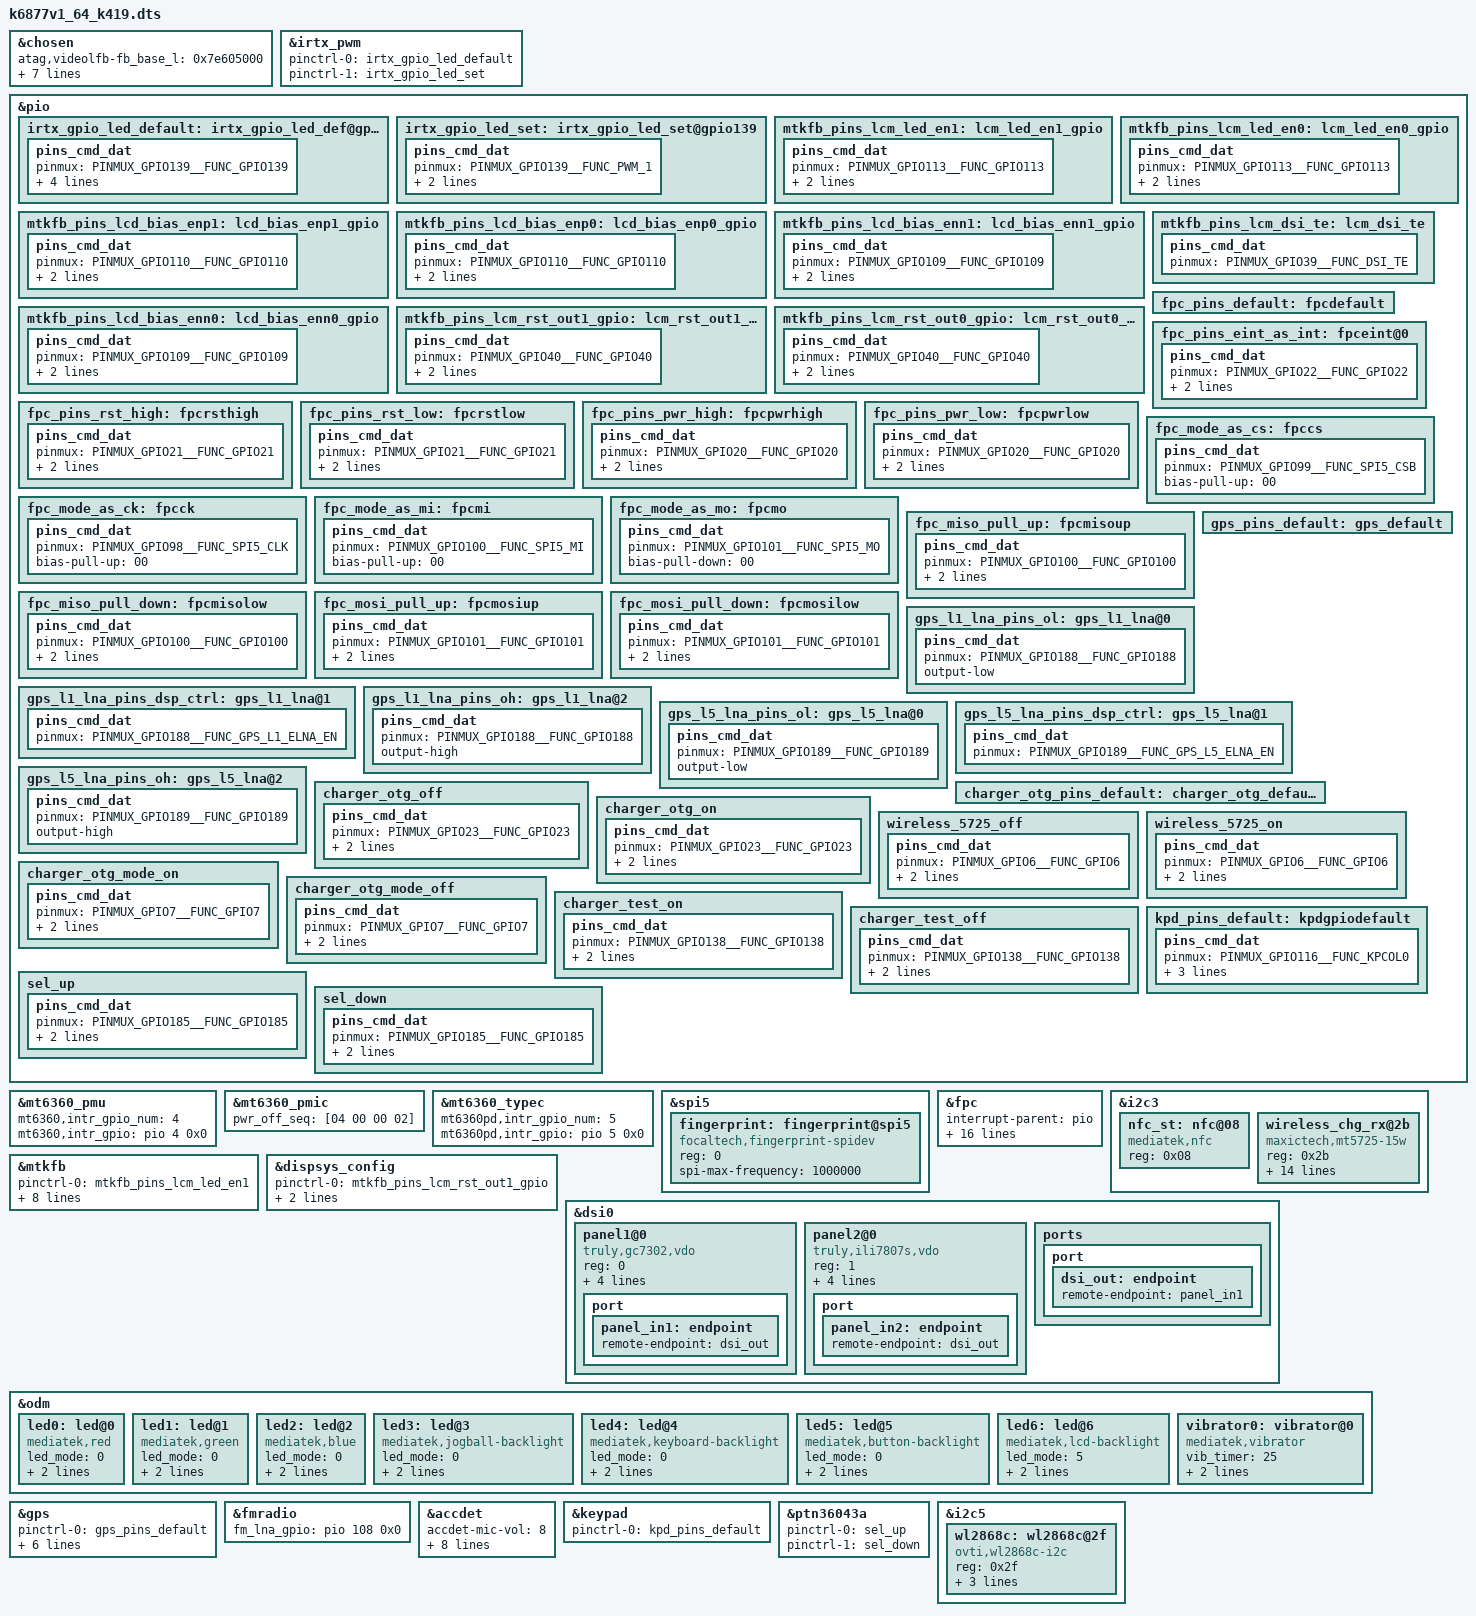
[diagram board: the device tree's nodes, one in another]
// SPDX-License-Identifier: GPL-2.0
/*
 * Copyright (c) 2021 MediaTek Inc.
 */

/dts-v1/;
/plugin/;
#include <dt-bindings/interrupt-controller/irq.h>
#include <dt-bindings/interrupt-controller/arm-gic.h>
#include <dt-bindings/pinctrl/mt6877-pinfunc.h>

/* chosen */
&chosen {
	atag,videolfb-fb_base_l = <0x7e605000>;
	atag,videolfb-fb_base_h = <0x0>;
	atag,videolfb-islcmfound = <1>;
	atag,videolfb-islcm_inited = <0>;
	atag,videolfb-fps= <6000>;
	atag,videolfb-vramSize= <0x1be0000>;
	atag,videolfb-lcmname=
		"gc7302_fhdp_dsi_vdo_auo_120hz_lcm_drv";
};

/* IRTX GPIO Start */
&irtx_pwm {
	pinctrl-names = "irtx_gpio_led_default", "irtx_gpio_led_set";
	pinctrl-0 = <&irtx_gpio_led_default>;
	pinctrl-1 = <&irtx_gpio_led_set>;
	status = "okay";
};
&pio {
	/* IRTX GPIO Settings -Start */
	/* default: GPIO0, output, high */
	irtx_gpio_led_default:irtx_gpio_led_def@gpio139 {
		pins_cmd_dat {
			pinmux = <PINMUX_GPIO139__FUNC_GPIO139>;
			slew-rate = <1>;
			bias-disable;
			output-low;
			input-schmitt-enable = <0>;
		};
	};

	irtx_gpio_led_set:irtx_gpio_led_set@gpio139 {
		pins_cmd_dat {
			pinmux = <PINMUX_GPIO139__FUNC_PWM_1>;
			slew-rate = <1>;
			output-high;
		};
	};
}; /* IRTX GPIO Settings -End */

&mt6360_pmu {
	mt6360,intr_gpio_num = <4>; /* direct defined GPIO num */
	mt6360,intr_gpio = <&pio 4 0x0>;
};

&mt6360_pmic {
	pwr_off_seq = [04 00 00 02];
};

&mt6360_typec {
	mt6360pd,intr_gpio_num = <5>; /* direct defined GPIO num */
	mt6360pd,intr_gpio = <&pio 5 0x0>;
};

&pio {
	mtkfb_pins_lcm_led_en1: lcm_led_en1_gpio {
		pins_cmd_dat {
			pinmux = <PINMUX_GPIO113__FUNC_GPIO113>;
			slew-rate = <1>;
			output-high;
		};
	};

	mtkfb_pins_lcm_led_en0: lcm_led_en0_gpio {
		pins_cmd_dat {
			pinmux = <PINMUX_GPIO113__FUNC_GPIO113>;
			slew-rate = <1>;
			output-low;
		};
	};

	mtkfb_pins_lcd_bias_enp1: lcd_bias_enp1_gpio {
		pins_cmd_dat {
			pinmux = <PINMUX_GPIO110__FUNC_GPIO110>;
			slew-rate = <1>;
			output-high;
		};
	};

	mtkfb_pins_lcd_bias_enp0: lcd_bias_enp0_gpio {
		pins_cmd_dat {
			pinmux = <PINMUX_GPIO110__FUNC_GPIO110>;
			slew-rate = <1>;
			output-low;
		};
	};

	mtkfb_pins_lcd_bias_enn1: lcd_bias_enn1_gpio {
		pins_cmd_dat {
			pinmux = <PINMUX_GPIO109__FUNC_GPIO109>;
			slew-rate = <1>;
			output-high;
		};
	};

	mtkfb_pins_lcd_bias_enn0: lcd_bias_enn0_gpio {
		pins_cmd_dat {
			pinmux = <PINMUX_GPIO109__FUNC_GPIO109>;
			slew-rate = <1>;
			output-low;
		};
	};

	mtkfb_pins_lcm_rst_out1_gpio: lcm_rst_out1_gpio {
		pins_cmd_dat {
			pinmux = <PINMUX_GPIO40__FUNC_GPIO40>;
			slew-rate = <1>;
			output-high;
		};
	};

	mtkfb_pins_lcm_rst_out0_gpio: lcm_rst_out0_gpio {
		pins_cmd_dat {
			pinmux = <PINMUX_GPIO40__FUNC_GPIO40>;
			slew-rate = <1>;
			output-low;
		};
	};
	mtkfb_pins_lcm_dsi_te: lcm_dsi_te {
		pins_cmd_dat {
			pinmux = <PINMUX_GPIO39__FUNC_DSI_TE>;
		};
	};
};

/* prize-add-pengzhipeng-20191011-start */
&spi5{
	#address-cells = <1>;
	#size-cells = <0>;
	fingerprint: fingerprint@spi5{
		compatible = "focaltech,fingerprint-spidev";
		reg = <0>;
		spi-max-frequency = <1000000>;
		status = "okay";
	};
};

&fpc {
	interrupt-parent = <&pio>;
	interrupts = <22 IRQ_TYPE_EDGE_RISING 22 0>;
	VFP-supply = <&mt_pmic_vfp_ldo_reg>;
	pinctrl-names = "default",
		"fpc_eint_as_int",
		"fpc_pins_rst_high", "fpc_pins_rst_low",
		"fpc_pins_pwr_high", "fpc_pins_pwr_low",
		"fpc_mode_as_cs", "fpc_mode_as_ck",
		"fpc_mode_as_mi", "fpc_mode_as_mo",
		"fpc_miso_pull_up", "fpc_miso_pull_down",
		"fpc_mosi_pull_up", "fpc_mosi_pull_down";
	pinctrl-0 = <&fpc_pins_default>;
	pinctrl-1 = <&fpc_pins_eint_as_int>;
	pinctrl-2 = <&fpc_pins_rst_high>;
	pinctrl-3 = <&fpc_pins_rst_low>;
	pinctrl-4 = <&fpc_pins_pwr_high>;
	pinctrl-5 = <&fpc_pins_pwr_low>;
	pinctrl-6 = <&fpc_mode_as_cs>;
	pinctrl-7 = <&fpc_mode_as_ck>;
	pinctrl-8= <&fpc_mode_as_mi>;
	pinctrl-9 = <&fpc_mode_as_mo>;
	pinctrl-10 = <&fpc_miso_pull_up>;
	pinctrl-11 = <&fpc_miso_pull_down>;
	pinctrl-12 = <&fpc_mosi_pull_up>;
	pinctrl-13 = <&fpc_mosi_pull_down>;
	status = "okay";
};
&pio {
	fpc_pins_default: fpcdefault {
	};

	fpc_pins_eint_as_int: fpceint@0 {
		pins_cmd_dat {
			pinmux = <PINMUX_GPIO22__FUNC_GPIO22>;
			slew-rate = <0>;
			bias-disable;
		};
	};
	fpc_pins_rst_high: fpcrsthigh {
		pins_cmd_dat {
			pinmux = <PINMUX_GPIO21__FUNC_GPIO21>;
			slew-rate = <1>;
			output-high;
		};
	};
	fpc_pins_rst_low: fpcrstlow {
		pins_cmd_dat {
			pinmux = <PINMUX_GPIO21__FUNC_GPIO21>;
			slew-rate = <1>;
			output-low;
		};
	};
	fpc_pins_pwr_high: fpcpwrhigh {
		pins_cmd_dat {
			pinmux = <PINMUX_GPIO20__FUNC_GPIO20>;
			slew-rate = <1>;
			output-high;
		};
	};
	fpc_pins_pwr_low: fpcpwrlow {
		pins_cmd_dat {
			pinmux = <PINMUX_GPIO20__FUNC_GPIO20>;
			slew-rate = <1>;
			output-low;
		};
	};	
	fpc_mode_as_cs: fpccs {
		pins_cmd_dat {
			pinmux = <PINMUX_GPIO99__FUNC_SPI5_CSB>;
			bias-pull-up = <00>;
		};
	};
	fpc_mode_as_ck: fpcck {
		pins_cmd_dat {
			pinmux = <PINMUX_GPIO98__FUNC_SPI5_CLK>;
			bias-pull-up = <00>;
		};
	};
	fpc_mode_as_mi: fpcmi {
		pins_cmd_dat {
			pinmux = <PINMUX_GPIO100__FUNC_SPI5_MI>;
			bias-pull-up = <00>;
		};
	};
	fpc_mode_as_mo: fpcmo {
		pins_cmd_dat {
			pinmux = <PINMUX_GPIO101__FUNC_SPI5_MO>;
			bias-pull-down = <00>;
		};
	};
	fpc_miso_pull_up: fpcmisoup {
		pins_cmd_dat {
			pinmux = <PINMUX_GPIO100__FUNC_GPIO100>;
			slew-rate = <1>;
			output-high;
		};
	};
	fpc_miso_pull_down: fpcmisolow {
		pins_cmd_dat {
			pinmux = <PINMUX_GPIO100__FUNC_GPIO100>;
			slew-rate = <1>;
			output-low;
		};
	};
	fpc_mosi_pull_up: fpcmosiup {
		pins_cmd_dat {
			pinmux = <PINMUX_GPIO101__FUNC_GPIO101>;
			slew-rate = <1>;
			output-high;
		};
	};
	fpc_mosi_pull_down: fpcmosilow {
		pins_cmd_dat {
			pinmux = <PINMUX_GPIO101__FUNC_GPIO101>;
			slew-rate = <1>;
			output-low;
		};
	};
};
/* prize-add-pengzhipeng-20191011-end */
/* prize-add nfc-pengzhipeng-20220316-start */
/*******************************************
* nfc st21
*******************************************/
&i2c3 {
	nfc_st:nfc@08 {
		compatible = "mediatek,nfc";
		reg = <0x08>;
		status = "okay";
	};
};
/* prize-add nfc-pengzhipeng-20220316-end */
&mtkfb {
	pinctrl-names = "lcm_led_en1_gpio", "lcm_led_en0_gpio",
		"lcd_bias_enp1_gpio", "lcd_bias_enp0_gpio",
		"lcd_bias_enn1_gpio", "lcd_bias_enn0_gpio",
		"lcm_rst_out1_gpio", "lcm_rst_out0_gpio",
		"mode_te_te";
	pinctrl-0 = <&mtkfb_pins_lcm_led_en1>;
	pinctrl-1 = <&mtkfb_pins_lcm_led_en0>;
	pinctrl-2 = <&mtkfb_pins_lcd_bias_enp1>;
	pinctrl-3 = <&mtkfb_pins_lcd_bias_enp0>;
	pinctrl-4 = <&mtkfb_pins_lcd_bias_enn1>;
	pinctrl-5 = <&mtkfb_pins_lcd_bias_enn0>;
	pinctrl-6 = <&mtkfb_pins_lcm_rst_out1_gpio>;
	pinctrl-7 = <&mtkfb_pins_lcm_rst_out0_gpio>;
	pinctrl-8 = <&mtkfb_pins_lcm_dsi_te>;
	status = "okay";
};
&dispsys_config {
	pinctrl-names =
		"lcm_rst_out1_gpio", "lcm_rst_out0_gpio",
		"mode_te_te";
	pinctrl-0 = <&mtkfb_pins_lcm_rst_out1_gpio>;
	pinctrl-1 = <&mtkfb_pins_lcm_rst_out0_gpio>;
	pinctrl-2 = <&mtkfb_pins_lcm_dsi_te>;
	status = "okay";
};

&dsi0 {
	status = "okay";
	#address-cells = <1>;
	#size-cells = <0>;
	panel1@0 {
		compatible = "truly,gc7302,vdo";
		reg = <0>;
		pm-enable-gpios = <&pio 107 0>;
		reset-gpios = <&pio 40 0>;
		ldo18-gpios = <&pio 184 0>;
		bias-gpios = <&pio 110 0>,
			<&pio 109 0>;
		pinctrl-names = "default";
		port {
			panel_in1: endpoint {
				remote-endpoint = <&dsi_out>;
			};
		};
	};
	panel2@0 {
		compatible = "truly,ili7807s,vdo";
		reg = <1>;
		pm-enable-gpios = <&pio 107 0>;
		reset-gpios = <&pio 40 0>;
		ldo18-gpios = <&pio 184 0>;
		bias-gpios = <&pio 110 0>,
			<&pio 109 0>;
		pinctrl-names = "default";
		port {
			panel_in2: endpoint {
				remote-endpoint = <&dsi_out>;
			};
		};
	};
	ports {
		port {
			dsi_out: endpoint {
				remote-endpoint = <&panel_in1>;
			};
		};
	};
};

&odm {
	led0:led@0 {
		compatible = "mediatek,red";
		led_mode = <0>;
		data = <1>;
		pwm_config = <0 0 0 0 0>;
	};
	led1:led@1 {
		compatible = "mediatek,green";
		led_mode = <0>;
		data = <1>;
		pwm_config = <0 0 0 0 0>;
	};
	led2:led@2 {
		compatible = "mediatek,blue";
		led_mode = <0>;
		data = <1>;
		pwm_config = <0 0 0 0 0>;
	};
	led3:led@3 {
		compatible = "mediatek,jogball-backlight";
		led_mode = <0>;
		data = <1>;
		pwm_config = <0 0 0 0 0>;
	};
	led4:led@4 {
		compatible = "mediatek,keyboard-backlight";
		led_mode = <0>;
		data = <1>;
		pwm_config = <0 0 0 0 0>;
	};
	led5:led@5 {
		compatible = "mediatek,button-backlight";
		led_mode = <0>;
		data = <1>;
		pwm_config = <0 0 0 0 0>;
	};
	led6:led@6 {
		compatible = "mediatek,lcd-backlight";
		led_mode = <5>;
		data = <1>;
		led_config = <8 11>;
	};
	vibrator0:vibrator@0 {
		compatible = "mediatek,vibrator";
		vib_timer = <25>;
		vib_limit = <11>;
		vib_vol= <11>;
	};
};

/* GPS GPIO standardization start */
&pio {
	gps_pins_default: gps_default {
	};
	gps_l1_lna_pins_ol: gps_l1_lna@0 {
		pins_cmd_dat {
			pinmux = <PINMUX_GPIO188__FUNC_GPIO188>;
			output-low;
		};
	};
	gps_l1_lna_pins_dsp_ctrl: gps_l1_lna@1 {
		pins_cmd_dat {
			pinmux = <PINMUX_GPIO188__FUNC_GPS_L1_ELNA_EN>;
		};
	};
	gps_l1_lna_pins_oh: gps_l1_lna@2 {
		pins_cmd_dat {
			pinmux = <PINMUX_GPIO188__FUNC_GPIO188>;
			output-high;
		};
	};
	gps_l5_lna_pins_ol: gps_l5_lna@0 {
		pins_cmd_dat {
			pinmux = <PINMUX_GPIO189__FUNC_GPIO189>;
			output-low;
		};
	};
	gps_l5_lna_pins_dsp_ctrl: gps_l5_lna@1 {
		pins_cmd_dat {
			pinmux = <PINMUX_GPIO189__FUNC_GPS_L5_ELNA_EN>;
		};
	};
	gps_l5_lna_pins_oh: gps_l5_lna@2 {
		pins_cmd_dat {
			pinmux = <PINMUX_GPIO189__FUNC_GPIO189>;
			output-high;
		};
	};
};
&gps {
	pinctrl-names = "default",
		"gps_l1_lna_disable",
		"gps_l1_lna_dsp_ctrl",
		"gps_l1_lna_enable",
		"gps_l5_lna_disable",
		"gps_l5_lna_dsp_ctrl",
		"gps_l5_lna_enable";
	pinctrl-0 = <&gps_pins_default>;
	pinctrl-1 = <&gps_l1_lna_pins_ol>;
	pinctrl-2 = <&gps_l1_lna_pins_dsp_ctrl>;
	pinctrl-3 = <&gps_l1_lna_pins_oh>;
	pinctrl-4 = <&gps_l5_lna_pins_ol>;
	pinctrl-5 = <&gps_l5_lna_pins_dsp_ctrl>;
	pinctrl-6 = <&gps_l5_lna_pins_oh>;
	status = "okay";
};
/* GPS GPIO standardization end */

/* prize pengzhipeng add fm, 20220316 start */

&fmradio {
	fm_lna_gpio = <&pio 108 0x0>;
	status = "okay";
};
/* prize pengzhipeng add fm, 20220316 end */
&accdet {
	/* accdet micbias voltage: 0x09:2.85v 0x08:2.8v 0x07,
	 * 2.7v;0x05,2.5v;0x02,1.9v
	 */
	accdet-mic-vol = <8>;
	/* accdet pwm_width, pwm_thresh, fall_delay, rise_delay
	 * debounce0, debounce1, debounce3, debounce4
	 * eint pwm_width, eint pwm_thresh
	 * eint deb(debounce0, debounce1, debounce2, debounce3), inv_debounce
	 */
	headset-mode-setting = <0x500 0x500 1 0x1f0
				0x800 0x800 0x20 0x44
				0x4 0x1
				0x5 0x3 0x3 0x5 0xe>;
	accdet-plugout-debounce = <1>;
	/*1:ACC mode, 2:low cost without in bias, 6:low cost with in bias*/
	accdet-mic-mode = <1>;
	/*0--MD_MAX--UP_MAX--DW_MAX*/
	headset-three-key-threshold = <0 80 220 400>;
	headset-three-key-threshold-CDD = <0 121 192 600>;
	/*0--MD_MAX--VOICE_MAX--UP_MAX--DW_MAX*/
	headset-four-key-threshold = <0 58 121 192 400>;

	/* select VTH to 2v and 500k, use internal resitance */
	eint_use_ext_res = <0>;
	status = "okay";
};

//prize add by lipengpeng wireless  start
&pio {
        charger_otg_pins_default: charger_otg_default {
        };
        charger_otg_off:  charger_otg_off {
            pins_cmd_dat {
                        pinmux = <PINMUX_GPIO23__FUNC_GPIO23>;
                        slew-rate = <1>;
                        output-low;
                };
        };
        charger_otg_on:  charger_otg_on {
            pins_cmd_dat {
                        pinmux = <PINMUX_GPIO23__FUNC_GPIO23>;
                        slew-rate = <1>;
                        output-high;
                };
        };
      wireless_5725_off:  wireless_5725_off {
            pins_cmd_dat {
                        pinmux = <PINMUX_GPIO6__FUNC_GPIO6>;
                        slew-rate = <1>;
                        output-high;
                };
        };
        wireless_5725_on:  wireless_5725_on {
            pins_cmd_dat {
                        pinmux = <PINMUX_GPIO6__FUNC_GPIO6>;
                        slew-rate = <1>;
                        output-low;
                };
        };
		charger_otg_mode_on:  charger_otg_mode_on {
            pins_cmd_dat {
                        pinmux = <PINMUX_GPIO7__FUNC_GPIO7>;
                        slew-rate = <1>;
                        output-high;
                };
        };
        charger_otg_mode_off:  charger_otg_mode_off {
            pins_cmd_dat {
                        pinmux = <PINMUX_GPIO7__FUNC_GPIO7>;
                        slew-rate = <1>;
                        output-low;
                };
        };
//prize add by lipengpeng 20210416 start BPI_BUS4  GPIO90
		charger_test_on:  charger_test_on {
            pins_cmd_dat {
                        pinmux = <PINMUX_GPIO138__FUNC_GPIO138>;
                        slew-rate = <1>;
                        output-high;
                };
        };
        charger_test_off:  charger_test_off {
            pins_cmd_dat {
                        pinmux = <PINMUX_GPIO138__FUNC_GPIO138>;
                        slew-rate = <1>;
                        output-low;
                };
        };
//prize add by lipengpeng 20210416 start BPI_BUS4  GPIO90
};
&i2c3 {
	wireless_chg_rx@2b {
		compatible = "maxictech,mt5725-15w";
		reg = <0x2b>;
		irq-gpio = <&pio 8 0>;//W_CHARGE_INT
		//trxset_gpio = <&pio 88 0>;//DC_EN
		//otgen_gpio = <&pio 87 0>;
		statu_gpio = <&pio 9 0>;//WRX_EN
		chipen_gpio = <&pio 7 0>;//CHARGE_EN
		//rx_power_capability = <10>;
		//one_pin_ctl = <1>;
		rx_power_capability = <15>;
	   one_pin_ctl = <0>;
	   pinctrl-names = "default", "charger_otg_off", "charger_otg_on",
				 "wireless_5725_off", "wireless_5725_on","charger_otg_mode_on","charger_otg_mode_off","test_gpio","test_off";
	   pinctrl-0 = <&charger_otg_pins_default>;
	   pinctrl-1 = <&charger_otg_off>;//WPC_OTG_EN
	   pinctrl-2 = <&charger_otg_on>;//WPC_OTG_EN
	   pinctrl-3 = <&wireless_5725_off>;//WPC_OTG_EN2
	   pinctrl-4 = <&wireless_5725_on>;//WPC_OTG_EN2
	   pinctrl-5 = <&charger_otg_mode_on>;//WPC_OTG_mode_on
	   pinctrl-6 = <&charger_otg_mode_off>;//WPC_OTG_mode_off
	   pinctrl-7 = <&charger_test_on>;//WPC_OTG_mode_on
	   pinctrl-8 = <&charger_test_off>;//WPC_OTG_mode_off
	};
};
//prize add by lipengpeng wireless  end
/* keypad start */
&keypad {
	pinctrl-names = "default";
	pinctrl-0 = <&kpd_pins_default>;
};

&pio {
	kpd_pins_default: kpdgpiodefault {
		pins_cmd_dat {
			pinmux = <PINMUX_GPIO116__FUNC_KPCOL0>;
			bias-pull-up = <MTK_PUPD_SET_R1R0_10>;
			input-enable;
			input-schmitt-enable;
		};
	};
};
/* keypad end */
//FIXME:prize-add-pengzhipeng-20220802-start
&ptn36043a {
	pinctrl-names = "sel_up", "sel_down";
	pinctrl-0 = <&sel_up>;
	pinctrl-1 = <&sel_down>;
	status = "okay";
};
&pio {
	sel_up: sel_up {
		pins_cmd_dat {
			pinmux = <PINMUX_GPIO185__FUNC_GPIO185>;
			slew-rate = <1>;
			output-low;
		};
	};

	sel_down: sel_down {
		pins_cmd_dat {
			pinmux = <PINMUX_GPIO185__FUNC_GPIO185>;
			slew-rate = <1>;
			output-high;
		};
	};
};
//FIXME:prize-add-pengzhipeng-20220802-end

/*prize add by zhuzhengjiang for camera ldo wl2868c  start*/ 
&i2c5 {
    status = "ok";
	wl2868c: wl2868c@2f {
		compatible = "ovti,wl2868c-i2c";
		reg = <0x2f>;
		id_reg = <0x00>;
		id_val = <0x82>;
		en-gpios = <&pio 162 0>;
	};
};
/*prize add by zhuzhengjiang for camera ldo wl2868c  end*/
#include "k6877v1_64_k419/cust.dtsi"
#include "mediatek/cust_mt6877_touch_1080x2300.dtsi"
#include "mediatek/cust_mt6877_camera.dtsi"
/*End of this file, DO NOT ADD ANYTHING HERE*/

